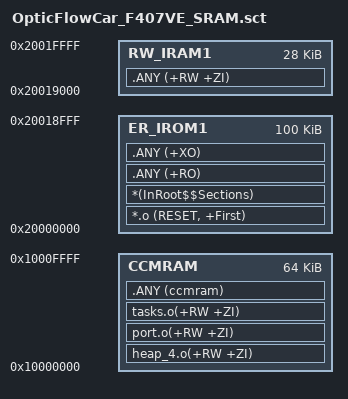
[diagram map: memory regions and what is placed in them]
; *************************************************************
; *** Scatter-Loading Description File generated by uVision ***
; *************************************************************

LR_IROM1 0x20000000 0x00019000  {    ; load region size_region
  ER_IROM1 0x20000000 0x00019000  {  ; load address = execution address
   *.o (RESET, +First)
   *(InRoot$$Sections)
   .ANY (+RO)
   .ANY (+XO)
  }
  RW_IRAM1 0x20019000 0x0007000  {  ; RW data
   .ANY (+RW +ZI)
  }
  CCMRAM 0x10000000 0x00010000 {
	  heap_4.o(+RW +ZI)
	  port.o(+RW +ZI)
	  tasks.o(+RW +ZI)
	  .ANY (ccmram)
  }
}

